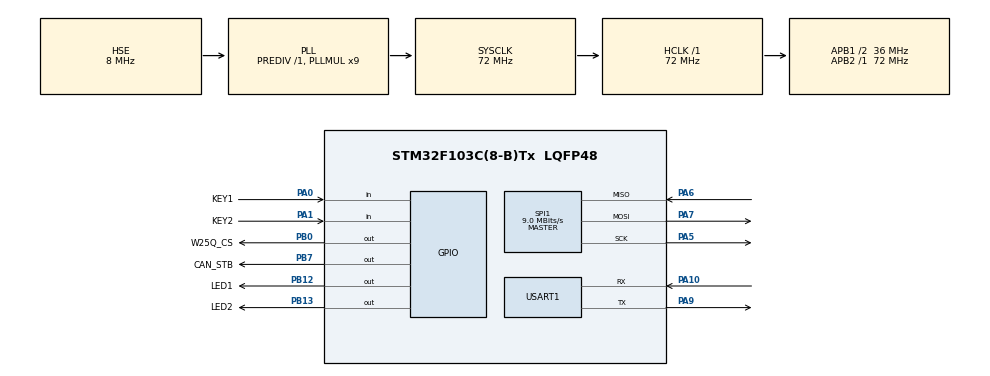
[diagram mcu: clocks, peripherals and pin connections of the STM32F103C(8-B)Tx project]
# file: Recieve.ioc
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Dma.Request0=USART1_RX
Dma.USART1_RX.0.Direction=DMA_PERIPH_TO_MEMORY
Dma.USART1_RX.0.Instance=DMA1_Channel5
Dma.USART1_RX.0.MemDataAlignment=DMA_MDATAALIGN_BYTE
Dma.USART1_RX.0.MemInc=DMA_MINC_ENABLE
Dma.USART1_RX.0.Mode=DMA_CIRCULAR
Dma.USART1_RX.0.PeriphDataAlignment=DMA_PDATAALIGN_BYTE
Dma.USART1_RX.0.PeriphInc=DMA_PINC_DISABLE
Dma.USART1_RX.0.Priority=DMA_PRIORITY_LOW
Mcu.Family=STM32F1
Mcu.Name=STM32F103C(8-B)Tx
Mcu.Package=LQFP48
NVIC.CAN1_SCE_IRQn=true\:0\:0\:false\:false\:true\:true\:true\:true
NVIC.DMA1_Channel5_IRQn=true\:0\:0\:false\:false\:true\:false\:true\:true
NVIC.PriorityGroup=NVIC_PRIORITYGROUP_4
NVIC.USART1_IRQn=true\:0\:0\:false\:false\:true\:true\:true\:true
NVIC.USB_LP_CAN1_RX0_IRQn=true\:0\:0\:false\:false\:true\:true\:true\:true
PA0-WKUP.GPIO_Label=KEY1
PA0-WKUP.Signal=GPIO_Input
PA1.GPIO_Label=KEY2
PA1.Signal=GPIO_Input
PA10.Mode=Asynchronous
PA10.Signal=USART1_RX
PA13.Mode=Serial_Wire
PA13.Signal=SYS_JTMS-SWDIO
PA14.Mode=Serial_Wire
PA14.Signal=SYS_JTCK-SWCLK
PA5.Mode=Full_Duplex_Master
PA5.Signal=SPI1_SCK
PA6.Mode=Full_Duplex_Master
PA6.Signal=SPI1_MISO
PA7.Mode=Full_Duplex_Master
PA7.Signal=SPI1_MOSI
PA9.Mode=Asynchronous
PA9.Signal=USART1_TX
PB0.GPIO_Label=W25Q_CS
PB0.GPIO_PuPd=GPIO_PULLUP
PB0.GPIO_Speed=GPIO_SPEED_FREQ_HIGH
PB0.PinState=GPIO_PIN_SET
PB0.Signal=GPIO_Output
PB12.GPIO_Label=LED1
PB12.Signal=GPIO_Output
PB13.GPIO_Label=LED2
PB13.Signal=GPIO_Output
PB7.GPIO_Label=CAN_STB
PB7.GPIO_PuPd=GPIO_PULLUP
PB7.PinState=GPIO_PIN_SET
PB7.Signal=GPIO_Output
PD0-OSC_IN.Mode=HSE-External-Oscillator
PD0-OSC_IN.Signal=RCC_OSC_IN
PD1-OSC_OUT.Mode=HSE-External-Oscillator
PD1-OSC_OUT.Signal=RCC_OSC_OUT
ProjectManager.HeapSize=0x200
ProjectManager.StackSize=0x400
ProjectManager.TargetToolchain=CMake
RCC.AHBFreq_Value=72000000
RCC.APB1CLKDivider=RCC_HCLK_DIV2
RCC.APB1Freq_Value=36000000
RCC.APB1TimFreq_Value=72000000
RCC.APB2Freq_Value=72000000
RCC.APB2TimFreq_Value=72000000
RCC.HCLKFreq_Value=72000000
RCC.PLLMUL=RCC_PLL_MUL9
RCC.PLLSourceVirtual=RCC_PLLSOURCE_HSE
RCC.SYSCLKFreq_VALUE=72000000
RCC.SYSCLKSource=RCC_SYSCLKSOURCE_PLLCLK
RCC.USBFreq_Value=72000000
SPI1.BaudRatePrescaler=SPI_BAUDRATEPRESCALER_8
SPI1.CalculateBaudRate=9.0 MBits/s
SPI1.Direction=SPI_DIRECTION_2LINES
SPI1.Mode=SPI_MODE_MASTER
SPI1.VirtualType=VM_MASTER
USART1.VirtualMode=VM_ASYNC
board=custom

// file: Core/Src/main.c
/* USER CODE BEGIN Header */
/**
  ******************************************************************************
  * @file           : main.c
  * @brief          : Main program body
  ******************************************************************************
  * @attention
  *
  * Copyright (c) 2026 STMicroelectronics.
  * All rights reserved.
  *
  * This software is licensed under terms that can be found in the LICENSE file
  * in the root directory of this software component.
  * If no LICENSE file comes with this software, it is provided AS-IS.
  *
  ******************************************************************************
  */
/* USER CODE END Header */
#include "main.h"
#include "dma.h"
#include "spi.h"
#include "usart.h"
#include "gpio.h"

/* USER CODE BEGIN Includes */
#include "board.h"
#include "Boot_Loader.h"
/* w25q_test.h 已删除（自检代码不再保留），原因见 main() 里的说明。
   ⚠ 2026-11-24：本行原先直接写出了「2 号用户代码段的开始标记」原文，CubeMX 用字符串
   查找定位用户代码段，会先命中这句注释，于是把 Includes 尾部到真正的结束标记之间整段
   当成用户代码重新插入 —— 生成出两个 int main()、工程编译不过。
   **注释里永远不要出现标记原文（段名 + BEGIN/END 的组合）。** */
/* 本轮新增：Boot_Loader_Init() 内部会设片内 Flash 写入起点 0x08005000。
   放在这里仅为说明依赖；函数声明在 Boot_Loader.h，无需额外 include 才能调用。 */
/* USER CODE END Includes */

void SystemClock_Config(void);

int main(void)
{

  /* MCU Configuration--------------------------------------------------------*/

  /* Reset of all peripherals, Initializes the Flash interface and the Systick. */
  HAL_Init();

  /* Configure the system clock */
  SystemClock_Config();

  /* Initialize all configured peripherals */
  MX_GPIO_Init();
  MX_DMA_Init();
  MX_USART1_UART_Init();
  /* 2026-11-24：CAN 初始化已从 Boot 移除。Boot 只做「读标志 -> 从 W25Q 搬 1MB 到片内
     -> 校验 -> 跳转」，不关心字节来自 CAN 还是串口；CAN 收包在 APP 侧完成。
     保留这段说明是为了让后来者知道：这里没有 MX_CAN_Init 是刻意为之，不是漏了。 */
  MX_SPI1_Init();
  /* USER CODE BEGIN 2 */
  Uart_Init();
	/* W25Q64 自检代码（w25q_test.c/.h）已随发布版从仓库移除：它只是开发阶段
	   确认接线/ID 的辅助手段，功能验证早已完成；W25q 绑定由 Boot_Loader_Init()
	   显式完成，不依赖自检副作用。需要重新排查硬件时从 git 历史恢复该文件。 */

	/* 本轮新增：初始化片内 Flash 落盘链路（设写入起点 = App 区 0x08005000）。
	   必须在 Uart_Init() 之后 —— 落盘进度日志走 UART_LOG，先开串口才打得出来。
	   副作用：不改 W25Q 自检行为；串口随后收到的字节会被写进片内 Flash 而非丢弃。 */
	Boot_Loader_Init();

	/* 上电 3 秒窗口。窗口期内串口收到数据 -> 返回并留在 OTA 收 bin；
	   一直没数据且 App 有效 -> 直接跳到 0x08005000，本函数不返回。
	   自检代码已移除，本函数直接跟在 Boot_Loader_Init() 之后。 */
	(void)Boot_Loader_BootWindow();

	uint16_t len = 0;
	uint32_t sum = 0;		/* 11156 字节没事，但换成 1MB 的固件时 uint16_t 会悄悄回绕 */
  /* USER CODE END 2 */

  /* Infinite loop */
  while (1)
  {

    /* USER CODE BEGIN 3 */
    len = Boot_Loader_Getlen();
    sum += len;
    if(len > 0)
    {
		  Uart_Printf(UART_LOG, "receive: %d  sum: %lu\r\n", len, sum);
    }
  }
  /* USER CODE END 3 */
}

void SystemClock_Config(void)
{
  RCC_OscInitTypeDef RCC_OscInitStruct = {0};
  RCC_ClkInitTypeDef RCC_ClkInitStruct = {0};

  /** Initializes the RCC Oscillators according to the specified parameters
  * in the RCC_OscInitTypeDef structure.
  */
  RCC_OscInitStruct.OscillatorType = RCC_OSCILLATORTYPE_HSE;
  RCC_OscInitStruct.HSEState = RCC_HSE_ON;
  RCC_OscInitStruct.HSEPredivValue = RCC_HSE_PREDIV_DIV1;
  RCC_OscInitStruct.HSIState = RCC_HSI_ON;
  RCC_OscInitStruct.PLL.PLLState = RCC_PLL_ON;
  RCC_OscInitStruct.PLL.PLLSource = RCC_PLLSOURCE_HSE;
  RCC_OscInitStruct.PLL.PLLMUL = RCC_PLL_MUL9;
  if (HAL_RCC_OscConfig(&RCC_OscInitStruct) != HAL_OK)
  {
    Error_Handler();
  }

  /** Initializes the CPU, AHB and APB buses clocks
  */
  RCC_ClkInitStruct.ClockType = RCC_CLOCKTYPE_HCLK|RCC_CLOCKTYPE_SYSCLK
                              |RCC_CLOCKTYPE_PCLK1|RCC_CLOCKTYPE_PCLK2;
  RCC_ClkInitStruct.SYSCLKSource = RCC_SYSCLKSOURCE_PLLCLK;
  RCC_ClkInitStruct.AHBCLKDivider = RCC_SYSCLK_DIV1;
  RCC_ClkInitStruct.APB1CLKDivider = RCC_HCLK_DIV2;
  RCC_ClkInitStruct.APB2CLKDivider = RCC_HCLK_DIV1;

  if (HAL_RCC_ClockConfig(&RCC_ClkInitStruct, FLASH_LATENCY_2) != HAL_OK)
  {
    Error_Handler();
  }
}

void Error_Handler(void)
{
  __disable_irq();
  while (1)
  {
  }
}
